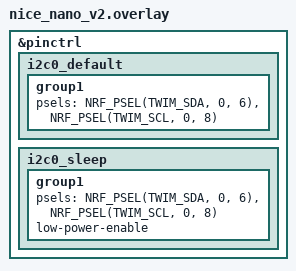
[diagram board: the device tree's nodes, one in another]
/*
 * Copyright (c) 2024 The ZMK Contributors
 * SPDX-License-Identifier: MIT
 *
 * Nice!Nano V2 specific pinctrl configuration for Apogee keyboard
 * This remaps I2C0 to P0.06 (SDA) and P0.08 (SCL)
 */

&pinctrl {
    i2c0_default: i2c0_default {
        group1 {
            psels = <NRF_PSEL(TWIM_SDA, 0, 6)>,
                    <NRF_PSEL(TWIM_SCL, 0, 8)>;
        };
    };

    i2c0_sleep: i2c0_sleep {
        group1 {
            psels = <NRF_PSEL(TWIM_SDA, 0, 6)>,
                    <NRF_PSEL(TWIM_SCL, 0, 8)>;
            low-power-enable;
        };
    };
};
